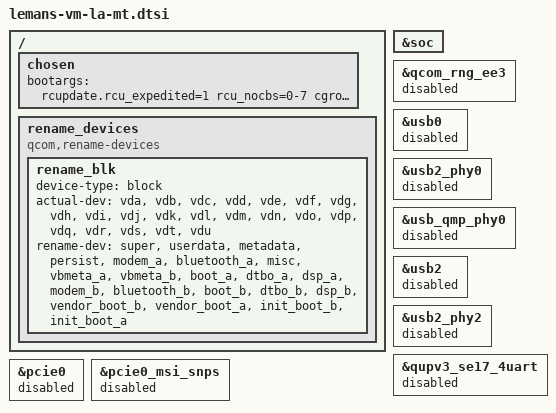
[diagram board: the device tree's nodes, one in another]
&soc {
};

/ {
	chosen {
		bootargs = "rcupdate.rcu_expedited=1 rcu_nocbs=0-7 cgroup.memory=nokmem,nosocket kpti=0 qcom_dma_heaps.enable_bitstream_contig_heap=y arm64.nopauth kasan=off msm_show_resume_irq.debug_mask=1 androidboot.usbcontroller=a600000.dwc3 androidboot.fstab_suffix=gen4.qcom";
	};

	rename_devices: rename_devices {
		compatible = "qcom,rename-devices";
		rename_blk: rename_blk {
			device-type = "block";
			actual-dev = "vda", "vdb", "vdc",
					"vdd", "vde", "vdf",
					"vdg", "vdh", "vdi",
					"vdj", "vdk", "vdl",
					"vdm", "vdn", "vdo",
					"vdp", "vdq", "vdr",
					"vds", "vdt", "vdu";
			rename-dev = "super", "userdata", "metadata",
					"persist", "modem_a","bluetooth_a",
					"misc", "vbmeta_a", "vbmeta_b",
					"boot_a", "dtbo_a", "dsp_a",
					"modem_b", "bluetooth_b", "boot_b",
					"dtbo_b", "dsp_b", "vendor_boot_b",
					"vendor_boot_a", "init_boot_b", "init_boot_a";
		};
	};
};

&qcom_rng_ee3 {
	status = "disabled";
};

&usb0 {
	status = "disabled";
};

&usb2_phy0 {
	status = "disabled";
};

&usb_qmp_phy0 {
	status = "disabled";
};

&usb2 {
	status = "disabled";
};

&usb2_phy2 {
	status = "disabled";
};

&qupv3_se17_4uart {
	status = "disabled";
};

&pcie0 {
	status = "disabled";
};

&pcie0_msi_snps {
	status = "disabled";
};
